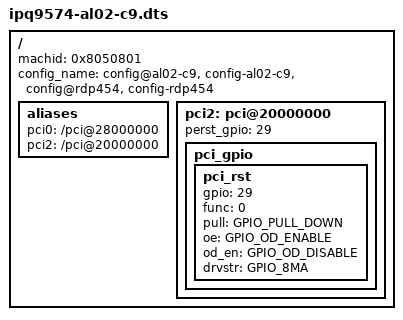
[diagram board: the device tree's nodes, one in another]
/*
 * Copyright (c) 2016-2021, The Linux Foundation. All rights reserved.
 * Copyright (c) 2022 Qualcomm Innovation Center, Inc. All rights reserved.
 *
 * This program is free software; you can redistribute it and/or modify
 * it under the terms of the GNU General Public License version 2 and
 * only version 2 as published by the Free Software Foundation.
 *
 * This program is distributed in the hope that it will be useful,
 * but WITHOUT ANY WARRANTY; without even the implied warranty of
 * MERCHANTABILITY or FITNESS FOR A PARTICULAR PURPOSE.  See the
 * GNU General Public License for more details.
 */

/dts-v1/;
#include "ipq9574-al01-c1.dts"
/ {
	machid = <0x8050801>;
	config_name = "config@al02-c9", "config-al02-c9", "config@rdp454", "config-rdp454";

	aliases {
		pci0 = "/pci@28000000";
		/delete-property/pci1;
		pci2 = "/pci@20000000";
	};

	pci2: pci@20000000 {
		status = "ok";
		perst_gpio = <29>;
		pci_gpio {
			pci_rst {
				gpio = <29>;
				func = <0>;
				pull = <GPIO_PULL_DOWN>;
				oe = <GPIO_OD_ENABLE>;
				od_en = <GPIO_OD_DISABLE>;
				drvstr = <GPIO_8MA>;
			};
		};
	};
};
